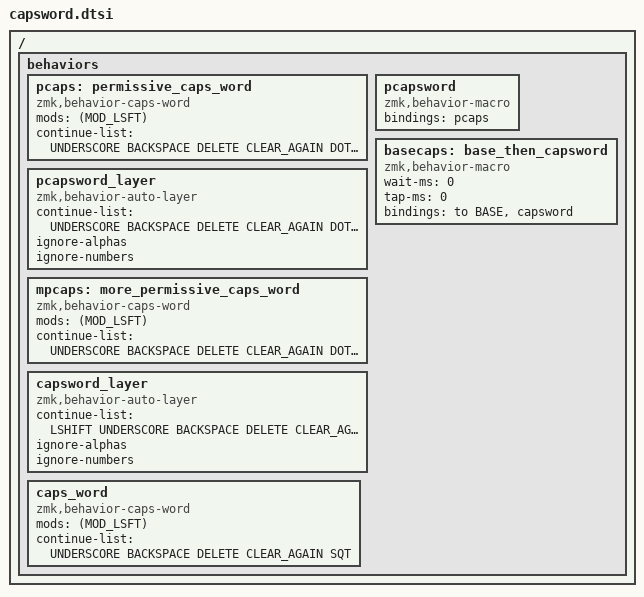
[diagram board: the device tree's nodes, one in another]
/ {
	behaviors {

		/* capswordy: capswordy { */
		/* 	compatible = "zmk,behavior-caps-word"; */
		/* 	#binding-cells = <0>; */
		/* 	mods = <(MOD_LSFT)>; */
		/* 	continue-list = < */
		/* 	UNDERSCORE */
		/* 	BACKSPACE DELETE */
		/* 	N1 N2 N3 N4 N5 N6 N7 N8 N9 N0 */
		/* 	>; */
		/* }; */
		


		pcaps: permissive_caps_word {
			compatible = "zmk,behavior-caps-word";
			#binding-cells = <0>;
			mods = <(MOD_LSFT)>;
      // Default: underscore, backspace, delete, alphanumerics
      // verður að taka aftur fram undrescore, backspace og delete
      // en alphanumerics koma sjálfkrafa
			continue-list = <
        UNDERSCORE BACKSPACE DELETE 
        CLEAR_AGAIN
        DOT COMMA MINUS 
      >;
		};

		pcapsword_layer: pcapsword_layer {
			compatible = "zmk,behavior-auto-layer";
			#binding-cells = <1>;
			continue-list = <
        UNDERSCORE BACKSPACE DELETE 
        CLEAR_AGAIN
        DOT COMMA MINUS 
      >;
			ignore-alphas;
			ignore-numbers;
		};

		pcapsword: pcapsword {
			compatible = "zmk,behavior-macro";
			#binding-cells = <0>;
			bindings = <
			&pcaps
			/* &pcapsword_layer CAPS_WORD_DOT */
			>;
		};


		mpcaps: more_permissive_caps_word {
			compatible = "zmk,behavior-caps-word";
			#binding-cells = <0>;
			mods = <(MOD_LSFT)>;
      // Default: underscore, backspace, delete, alphanumerics
      // verður að taka aftur fram undrescore, backspace og delete
      // en alphanumerics koma sjálfkrafa
      // ókei WEIRD ! virðist vera continue by default en ekki ?
			continue-list = <
        UNDERSCORE BACKSPACE DELETE 
        CLEAR_AGAIN
        DOT COMMA MINUS 
        SPACE QMARK
        DQT SQT
        LEFT RIGHT DOWN UP
      >;
		};

		capsword_layer: capsword_layer {
			compatible = "zmk,behavior-auto-layer";
			#binding-cells = <1>;
			continue-list = <LSHIFT UNDERSCORE BACKSPACE DELETE CLEAR_AGAIN>;
			ignore-alphas;
			ignore-numbers;
		};

		caps_word: caps_word {
			compatible = "zmk,behavior-caps-word";
			#binding-cells = <0>;
			mods = <(MOD_LSFT)>;
      // Default: underscore, backspace, delete, alphanumerics
      // verður að taka aftur fram undrescore, backspace og delete
      // en alphanumerics koma sjálfkrafa
			continue-list = <
        UNDERSCORE BACKSPACE DELETE 
        CLEAR_AGAIN
        SQT
			>;
		};

    #define capsword caps_word
		/* capsword: capsword { */
		/* 	compatible = "zmk,behavior-macro"; */
		/* 	#binding-cells = <0>; */
		/* Order matters: turn on Caps Word first, then the layer */
		/* 	bindings = < */
		/* 	&caps_word */
		/* 	&capsword_layer CAPS_WORD */
		/* 	>; */
		/* }; */

		basecaps: base_then_capsword {
			compatible = "zmk,behavior-macro";
			#binding-cells = <0>;
			wait-ms = <0>;
			tap-ms = <0>;
			bindings = <&to BASE>, <&capsword>;
		};

	};
};
